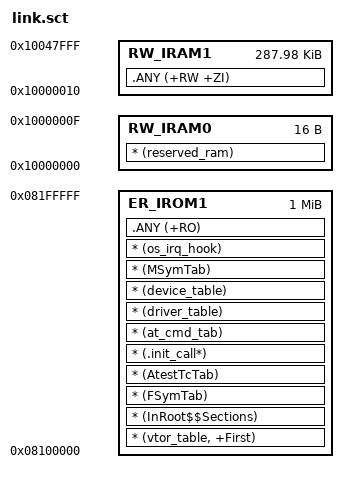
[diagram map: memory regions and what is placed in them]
; *************************************************************
; *** Scatter-Loading Description File generated by uVision ***
; *************************************************************

LR_IROM1 0x08100000 0x00100000  {    ; load region size_region
  ER_IROM1 0x08100000 0x00100000  {  ; load address = execution address
   * (vtor_table, +First)
   * (InRoot$$Sections)
   * (FSymTab)
   * (AtestTcTab)
   * (.init_call*)
   * (at_cmd_tab)
   * (driver_table)
   * (device_table)
   * (MSymTab)
   * (os_irq_hook)
   .ANY (+RO)
  }

  RW_IRAM0 0x10000000 0x10  {  ; RW data
   * (reserved_ram)
  }

  RW_IRAM1 0x10000010 0x47ff0 {  ; RW data
   .ANY (+RW +ZI)
  }
}

